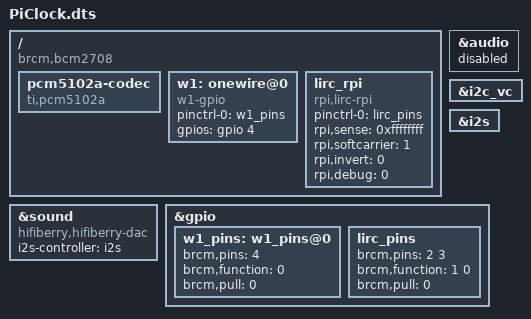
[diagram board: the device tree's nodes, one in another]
// Definitions for HiFiBerry DAC
/dts-v1/;
/plugin/;

/ {
	compatible = "brcm,bcm2708", "brcm,bcm2709";

    fragment@0 {
		target = <&audio>;
		__overlay__ {
			status = "disabled";
		};
	};

	fragment@1 {
		target = <&sound>;
		__overlay__ {
			compatible = "hifiberry,hifiberry-dac";
			i2s-controller = <&i2s>;
			status = "okay";
		};
	};

	fragment@2 {
		target = <&i2c_vc>;
		__overlay__ {
			status = "okay";
		};
	};	

	fragment@3 {
		target = <&i2s>;
		__overlay__ {
			status = "okay";
		};
	};

	fragment@4 {
		target-path = "/";
		__overlay__ {
			pcm5102a-codec {
				#sound-dai-cells = <0>;
				compatible = "ti,pcm5102a";
				status = "okay";
			};
		};
	};

	fragment@5 {
		target-path = "/";
		__overlay__ {

			w1: onewire@0 {
				compatible = "w1-gpio";
				pinctrl-names = "default";
				pinctrl-0 = <&w1_pins>;
				gpios = <&gpio 4 0>;
				status = "okay";
			};
		};
	};

	fragment@6 {
		target = <&gpio>;
		__overlay__ {
			w1_pins: w1_pins@0 {
				brcm,pins = <4>;
				brcm,function = <0>; // in (initially)
				brcm,pull = <0>; // off
			};
		};
	};

	__overrides__ {
		gpiopin =       <&w1>,"gpios:4",
				<&w1>,"reg:0",
				<&w1_pins>,"brcm,pins:0",
				<&w1_pins>,"reg:0";
		gpio_out_pin =  <&lirc_pins>,"brcm,pins:0";
		gpio_in_pin =   <&lirc_pins>,"brcm,pins:4";
		gpio_in_pull =  <&lirc_pins>,"brcm,pull:4";

		sense =         <&lirc_rpi>,"rpi,sense:0";
		softcarrier =   <&lirc_rpi>,"rpi,softcarrier:0";
		invert =        <&lirc_rpi>,"rpi,invert:0";
		debug =         <&lirc_rpi>,"rpi,debug:0";
		pullup;		// Silently ignore unneeded parameter
	};

	fragment@7 {
		target-path = "/";
		__overlay__ {
			lirc_rpi: lirc_rpi {
				compatible = "rpi,lirc-rpi";
				pinctrl-names = "default";
				pinctrl-0 = <&lirc_pins>;
				status = "okay";

				// Override autodetection of IR receiver circuit
				// (0 = active high, 1 = active low, -1 = no override )
				rpi,sense = <0xffffffff>;

				// Software carrier
				// (0 = off, 1 = on)
				rpi,softcarrier = <1>;

				// Invert output
				// (0 = off, 1 = on)
				rpi,invert = <0>;

				// Enable debugging messages
				// (0 = off, 1 = on)
				rpi,debug = <0>;
			};
		};
	};

	fragment@8 {
		target = <&gpio>;
		__overlay__ {
			lirc_pins: lirc_pins {
				brcm,pins = <2 3>;
				brcm,function = <1 0>; // out in
				brcm,pull = <0>; // off
			};
		};
	};
};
